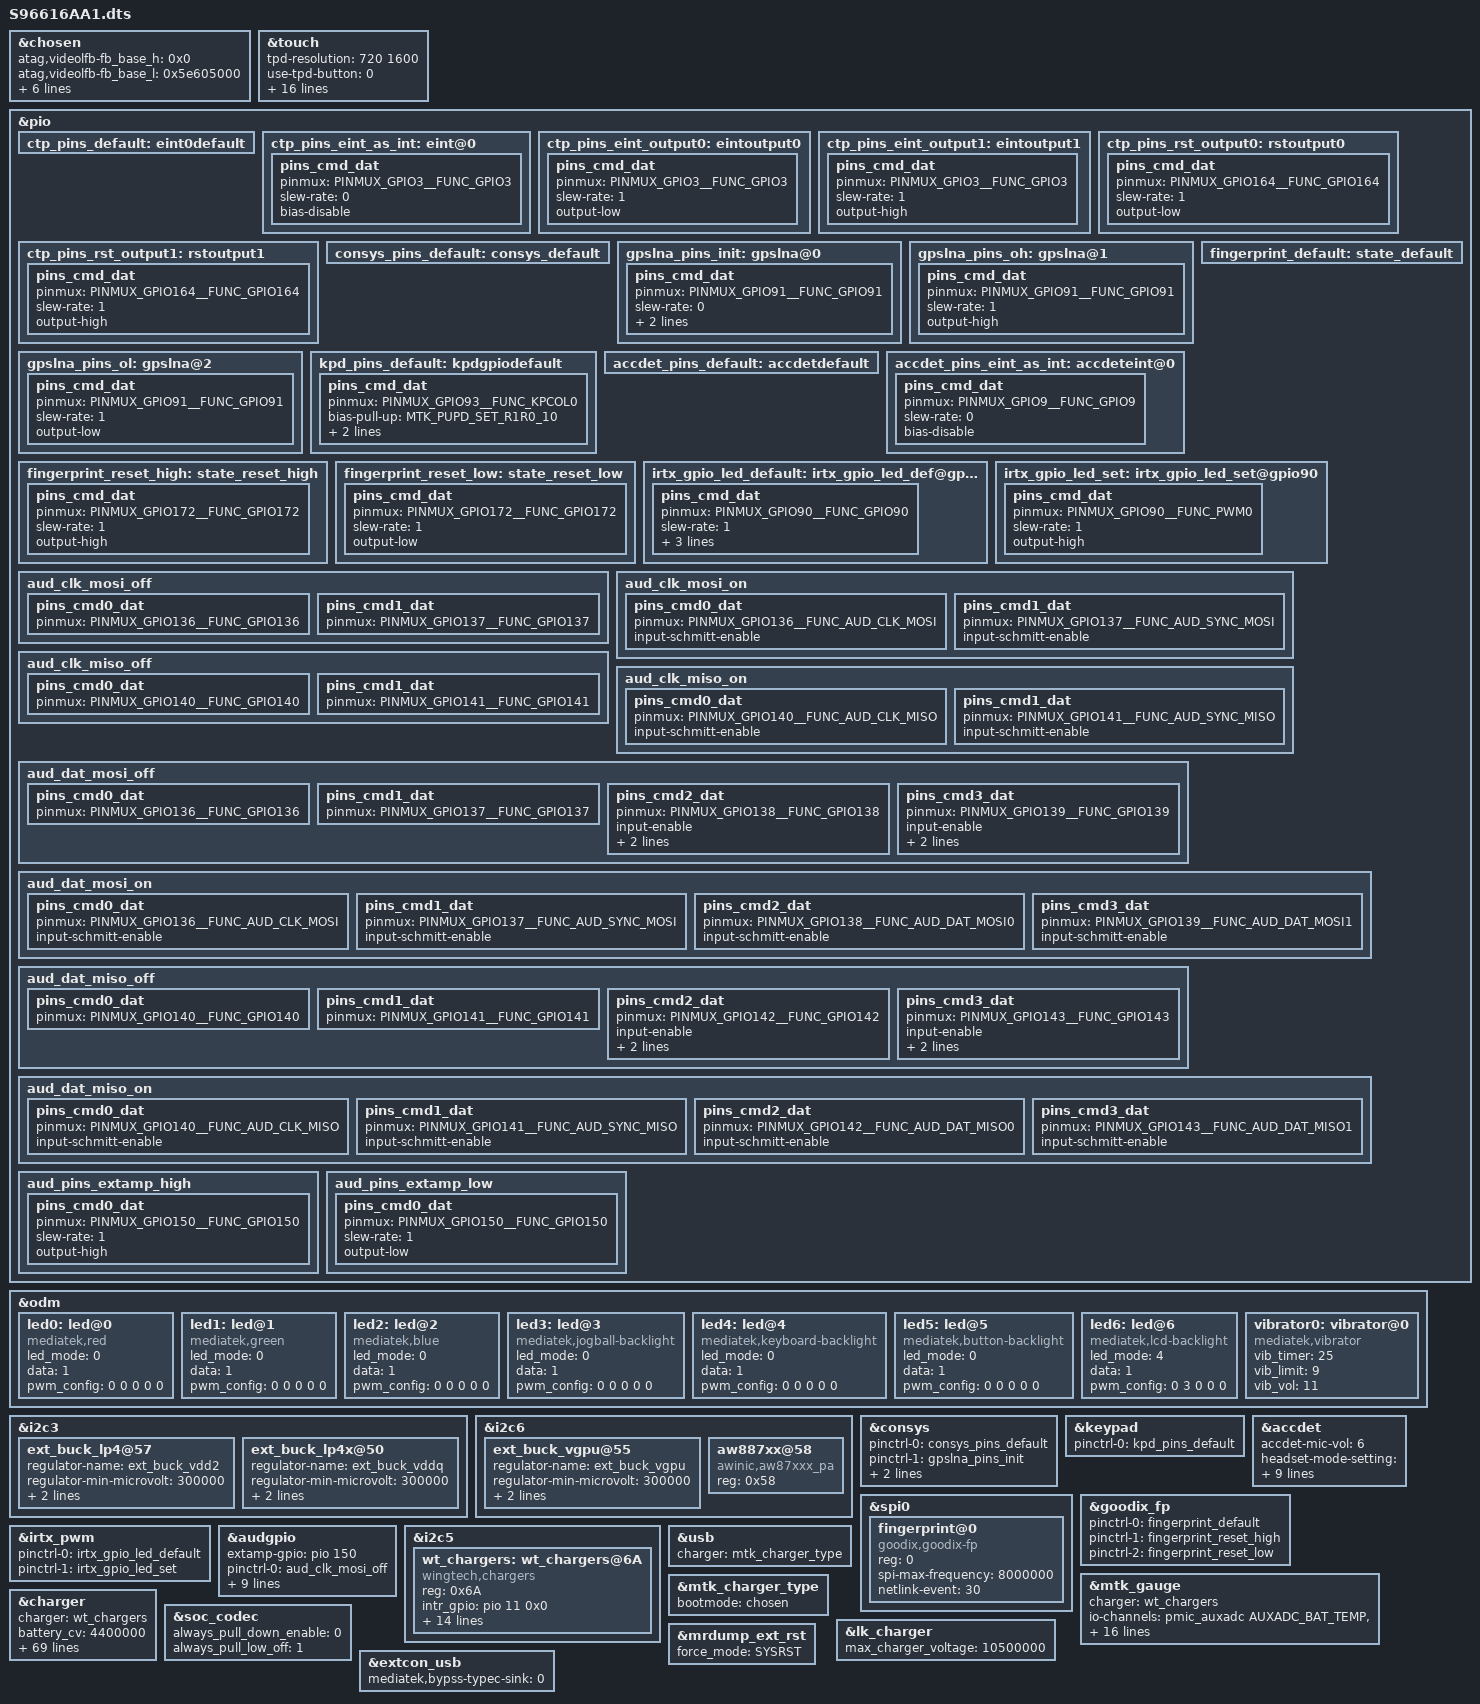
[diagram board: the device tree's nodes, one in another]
// SPDX-License-Identifier: GPL-2.0+
/*
 * Copyright (c) 2019 MediaTek Inc.
 *
 */

#include <dt-bindings/interrupt-controller/arm-gic.h>
#include <dt-bindings/interrupt-controller/irq.h>
#include <dt-bindings/pinctrl/mt6765-pinfunc.h>
#include <dt-bindings/clock/mt6765-clk.h>

/dts-v1/;
/plugin/;

/* chosen */
&chosen {

	/* fpga may has no lk, we need to specify display info here */
	/* fb buffer is reserved using this dts by memory node above */
	atag,videolfb-fb_base_h = <0x0>;
	atag,videolfb-fb_base_l = <0x5e605000>;
	atag,videolfb-islcmfound = <1>;
	/* because no lk, so lcm is not inited */
	atag,videolfb-islcm_inited = <0>;
	atag,videolfb-fps= <6000>;
	atag,videolfb-vramSize= <0x017bb000>;
	atag,videolfb-lcmname= "nt35695B_fhd_dsi_cmd_auo_rt5081_drv";
};

/* TOUCH start */
&touch {
	tpd-resolution = <720 1600>;
	use-tpd-button = <0>;
	tpd-key-num = <3>;
	tpd-key-local= <139 172 158 0>;
	tpd-key-dim-local = <200 2000 100 40 515 2000 100 40 800 2000 100 40 0 0 0 0>;
	tpd-max-touch-num = <10>;
	tpd-filter-enable = <0>;
	tpd-filter-pixel-density = <192>;
	tpd-filter-custom-prameters = <0 0 0 0 0 0 0 0 0 0 0 0>;
	tpd-filter-custom-speed = <0 0 0>;
	pinctrl-names = "default", "state_eint_as_int", "state_eint_output0",
		"state_eint_output1", "state_rst_output0", "state_rst_output1";
	pinctrl-0 = <&ctp_pins_default>;
	pinctrl-1 = <&ctp_pins_eint_as_int>;
	pinctrl-2 = <&ctp_pins_eint_output0>;
	pinctrl-3 = <&ctp_pins_eint_output1>;
	pinctrl-4 = <&ctp_pins_rst_output0>;
	pinctrl-5 = <&ctp_pins_rst_output1>;
	status = "okay";
};
&pio {
	ctp_pins_default: eint0default {
	};
	ctp_pins_eint_as_int: eint@0 {
		pins_cmd_dat {
			pinmux = <PINMUX_GPIO3__FUNC_GPIO3>;
			slew-rate = <0>;
			bias-disable;
		};
	};
	ctp_pins_eint_output0: eintoutput0 {
		pins_cmd_dat {
			pinmux = <PINMUX_GPIO3__FUNC_GPIO3>;
			slew-rate = <1>;
			output-low;
		};
	};
	ctp_pins_eint_output1: eintoutput1 {
		pins_cmd_dat {
			pinmux = <PINMUX_GPIO3__FUNC_GPIO3>;
			slew-rate = <1>;
			output-high;
		};
	};
	ctp_pins_rst_output0: rstoutput0 {
		pins_cmd_dat {
			pinmux = <PINMUX_GPIO164__FUNC_GPIO164>;
			slew-rate = <1>;
			output-low;
		};
	};
	ctp_pins_rst_output1: rstoutput1 {
		pins_cmd_dat {
			pinmux = <PINMUX_GPIO164__FUNC_GPIO164>;
			slew-rate = <1>;
			output-high;
		};
	};
};
/* TOUCH end */

&odm {
	led0:led@0 {
		compatible = "mediatek,red";
		led_mode = <0>;
		data = <1>;
		pwm_config = <0 0 0 0 0>;
	};
	led1:led@1 {
		compatible = "mediatek,green";
		led_mode = <0>;
		data = <1>;
		pwm_config = <0 0 0 0 0>;
	};
	led2:led@2 {
		compatible = "mediatek,blue";
		led_mode = <0>;
		data = <1>;
		pwm_config = <0 0 0 0 0>;
	};
	led3:led@3 {
		compatible = "mediatek,jogball-backlight";
		led_mode = <0>;
		data = <1>;
		pwm_config = <0 0 0 0 0>;
	};
	led4:led@4 {
		compatible = "mediatek,keyboard-backlight";
		led_mode = <0>;
		data = <1>;
		pwm_config = <0 0 0 0 0>;
	};
	led5:led@5 {
		compatible = "mediatek,button-backlight";
		led_mode = <0>;
		data = <1>;
		pwm_config = <0 0 0 0 0>;
	};
	led6:led@6 {
		compatible = "mediatek,lcd-backlight";
		led_mode = <4>;
		data = <1>;
		pwm_config = <0 3 0 0 0>;
	};
	vibrator0:vibrator@0 {
		compatible = "mediatek,vibrator";
		vib_timer = <25>;
		vib_limit = <9>;
		vib_vol= <11>;
	};
};

&i2c3 {
	ext_buck_lp4@57 {
		regulator-name ="ext_buck_vdd2";
		regulator-min-microvolt = <300000>;
		regulator-max-microvolt = <1300000>;
		vsel_pin = <0>;
	};

	ext_buck_lp4x@50 {
		regulator-name ="ext_buck_vddq";
		regulator-min-microvolt = <300000>;
		regulator-max-microvolt = <1300000>;
		vsel_pin = <1>;
	};
};

&i2c6 {
	ext_buck_vgpu@55 {
		regulator-name ="ext_buck_vgpu";
		regulator-min-microvolt = <300000>;
		regulator-max-microvolt = <1300000>;
		vsel_pin = <2>;
	};
};

&i2c6 {
    aw887xx@58 {
         compatible = "awinic,aw87xxx_pa";
         reg = <0x58>;
         status = "okay";
    };
};

/* CONSYS GPIO standardization */
&pio {
	consys_pins_default: consys_default {
	};
	gpslna_pins_init: gpslna@0 {
		pins_cmd_dat {
			pinmux = <PINMUX_GPIO91__FUNC_GPIO91>;
			slew-rate = <0>;
			bias-disable;
			output-low;
		};
	};
	gpslna_pins_oh: gpslna@1 {
		pins_cmd_dat {
			pinmux = <PINMUX_GPIO91__FUNC_GPIO91>;
			slew-rate = <1>;
			output-high;
		};
	};
	gpslna_pins_ol: gpslna@2 {
		pins_cmd_dat {
			pinmux = <PINMUX_GPIO91__FUNC_GPIO91>;
			slew-rate = <1>;
			output-low;
		};
	};
};
&consys {
	pinctrl-names = "default", "gps_lna_state_init",
		"gps_lna_state_oh", "gps_lna_state_ol";
	pinctrl-0 = <&consys_pins_default>;
	pinctrl-1 = <&gpslna_pins_init>;
	pinctrl-2 = <&gpslna_pins_oh>;
	pinctrl-3 = <&gpslna_pins_ol>;
	status = "okay";
};
/* CONSYS end */

&keypad {
	pinctrl-names = "default";
	pinctrl-0 = <&kpd_pins_default>;
};

&pio {
	kpd_pins_default: kpdgpiodefault {
		pins_cmd_dat {
			pinmux = <PINMUX_GPIO93__FUNC_KPCOL0>;
			bias-pull-up = <MTK_PUPD_SET_R1R0_10>;
			output-low;
			input-schmitt-enable;
		};
	};
};


/* accdet start */
&accdet {
	accdet-mic-vol = <6>;
	headset-mode-setting = <0x500 0x500 1 0x1f0 0x800 0x800 0x20 0x44>;
	accdet-plugout-debounce = <1>;
	accdet-mic-mode = <1>;
	headset-eint-level-pol = <8>;
	headset-three-key-threshold = <0 80 220 400>;
	headset-three-key-threshold-CDD = <0 121 192 600>;
	headset-four-key-threshold = <0 58 121 192 400>;
	pinctrl-names = "default", "state_eint_as_int";
	pinctrl-0 = <&accdet_pins_default>;
	pinctrl-1 = <&accdet_pins_eint_as_int>;
	status = "okay";
};
&pio {
	accdet_pins_default: accdetdefault {
	};
	accdet_pins_eint_as_int: accdeteint@0 {
		pins_cmd_dat {
			pinmux = <PINMUX_GPIO9__FUNC_GPIO9>;
			slew-rate = <0>;
			bias-disable;
		};
	};
};
/* accdet end */

/* FINGERPRINT start */
&spi0 {
	#address-cells = <1>;
	#size-cells = <0>;
	fingerprint@0 {
		compatible = "goodix,goodix-fp";
		reg = <0>;
		spi-max-frequency = <8000000>;
		netlink-event = <30>;
		status = "okay";
	};
};

&goodix_fp {
	pinctrl-names = "default", "reset_high", "reset_low";
	pinctrl-0 = <&fingerprint_default>;
	pinctrl-1 = <&fingerprint_reset_high>;
	pinctrl-2 = <&fingerprint_reset_low>;
	status = "okay";
};

&pio {
	fingerprint_default: state_default {
	};
	fingerprint_reset_high: state_reset_high {
		pins_cmd_dat {
			pinmux = <PINMUX_GPIO172__FUNC_GPIO172>;
			slew-rate = <1>;
			output-high;
		};
	};
	fingerprint_reset_low: state_reset_low {
		pins_cmd_dat {
			pinmux = <PINMUX_GPIO172__FUNC_GPIO172>;
			slew-rate = <1>;
			output-low;
		};
	};
};
/* FINGERPRINT end */

/* IRTX GPIO end */
&irtx_pwm {
	pinctrl-names = "irtx_gpio_led_default", "irtx_gpio_led_set";
	pinctrl-0 = <&irtx_gpio_led_default>;
	pinctrl-1 = <&irtx_gpio_led_set>;
	status = "okay";
};
&pio {
	irtx_gpio_led_default:irtx_gpio_led_def@gpio90 {
		pins_cmd_dat {
			pinmux = <PINMUX_GPIO90__FUNC_GPIO90>;
			slew-rate = <1>;
			bias-disable;
			output-low;
			input-schmitt-enable = <0>;
		};
	};

	irtx_gpio_led_set:irtx_gpio_led_set@gpio90 {
		pins_cmd_dat {
			pinmux = <PINMUX_GPIO90__FUNC_PWM0>;
			slew-rate = <1>;
			output-high;
		};
	};
};
/* IRTX GPIO Settings -End */

/* AUDIO GPIO standardization */
&audgpio {
	extamp-gpio = <&pio 150 0>;
	pinctrl-names = "aud_clk_mosi_off",
			"aud_clk_mosi_on",
			"aud_clk_miso_off",
			"aud_clk_miso_on",
			"aud_dat_mosi_off",
			"aud_dat_mosi_on",
			"aud_dat_miso_off",
			"aud_dat_miso_on",
			"extamp_pullhigh",
			"extamp_pulllow";
	pinctrl-0 = <&aud_clk_mosi_off>;
	pinctrl-1 = <&aud_clk_mosi_on>;
	pinctrl-2 = <&aud_clk_miso_off>;
	pinctrl-3 = <&aud_clk_miso_on>;
	pinctrl-4 = <&aud_dat_mosi_off>;
	pinctrl-5 = <&aud_dat_mosi_on>;
	pinctrl-6 = <&aud_dat_miso_off>;
	pinctrl-7 = <&aud_dat_miso_on>;
	pinctrl-8 = <&aud_pins_extamp_high>;
	pinctrl-9 = <&aud_pins_extamp_low>;
	status = "okay";
};

&pio {
	aud_clk_mosi_off: aud_clk_mosi_off {
		pins_cmd0_dat {
			pinmux = <PINMUX_GPIO136__FUNC_GPIO136>;
		};
		pins_cmd1_dat {
			pinmux = <PINMUX_GPIO137__FUNC_GPIO137>;
		};

	};

	aud_clk_mosi_on: aud_clk_mosi_on {
		pins_cmd0_dat {
			pinmux = <PINMUX_GPIO136__FUNC_AUD_CLK_MOSI>;
			input-schmitt-enable;
		};
		pins_cmd1_dat {
			pinmux = <PINMUX_GPIO137__FUNC_AUD_SYNC_MOSI>;
			input-schmitt-enable;
		};
	};

	aud_clk_miso_off: aud_clk_miso_off {
		pins_cmd0_dat {
			pinmux = <PINMUX_GPIO140__FUNC_GPIO140>;
		};
		pins_cmd1_dat {
			pinmux = <PINMUX_GPIO141__FUNC_GPIO141>;
		};
	};

	aud_clk_miso_on: aud_clk_miso_on {
		pins_cmd0_dat {
			pinmux = <PINMUX_GPIO140__FUNC_AUD_CLK_MISO>;
			input-schmitt-enable;
		};
		pins_cmd1_dat {
			pinmux = <PINMUX_GPIO141__FUNC_AUD_SYNC_MISO>;
			input-schmitt-enable;
		};
	};

	aud_dat_mosi_off: aud_dat_mosi_off {
		pins_cmd0_dat {
			pinmux = <PINMUX_GPIO136__FUNC_GPIO136>;
		};
		pins_cmd1_dat {
			pinmux = <PINMUX_GPIO137__FUNC_GPIO137>;
		};
		pins_cmd2_dat {
			pinmux = <PINMUX_GPIO138__FUNC_GPIO138>;
			input-enable;
			slew-rate = <0>;
			bias-disable;
		};
		pins_cmd3_dat {
			pinmux = <PINMUX_GPIO139__FUNC_GPIO139>;
			input-enable;
			slew-rate = <0>;
			bias-disable;
		};
	};

	aud_dat_mosi_on: aud_dat_mosi_on {
		pins_cmd0_dat {
			pinmux = <PINMUX_GPIO136__FUNC_AUD_CLK_MOSI>;
			input-schmitt-enable;
		};
		pins_cmd1_dat {
			pinmux = <PINMUX_GPIO137__FUNC_AUD_SYNC_MOSI>;
			input-schmitt-enable;
		};
		pins_cmd2_dat {
			pinmux = <PINMUX_GPIO138__FUNC_AUD_DAT_MOSI0>;
			input-schmitt-enable;
		};
		pins_cmd3_dat {
			pinmux = <PINMUX_GPIO139__FUNC_AUD_DAT_MOSI1>;
			input-schmitt-enable;
		};
	};

	aud_dat_miso_off: aud_dat_miso_off {
		pins_cmd0_dat {
			pinmux = <PINMUX_GPIO140__FUNC_GPIO140>;
		};
		pins_cmd1_dat {
			pinmux = <PINMUX_GPIO141__FUNC_GPIO141>;
		};
		pins_cmd2_dat {
			pinmux = <PINMUX_GPIO142__FUNC_GPIO142>;
			input-enable;
			slew-rate = <0>;
			bias-disable;
		};
		pins_cmd3_dat {
			pinmux = <PINMUX_GPIO143__FUNC_GPIO143>;
			input-enable;
			slew-rate = <0>;
			bias-disable;
		};
	};
	aud_dat_miso_on: aud_dat_miso_on {
		pins_cmd0_dat {
			pinmux = <PINMUX_GPIO140__FUNC_AUD_CLK_MISO>;
			input-schmitt-enable;
		};
		pins_cmd1_dat {
			pinmux = <PINMUX_GPIO141__FUNC_AUD_SYNC_MISO>;
			input-schmitt-enable;
		};
		pins_cmd2_dat {
			pinmux = <PINMUX_GPIO142__FUNC_AUD_DAT_MISO0>;
			input-schmitt-enable;
		};
		pins_cmd3_dat {
			pinmux = <PINMUX_GPIO143__FUNC_AUD_DAT_MISO1>;
			input-schmitt-enable;
		};
	};

	aud_pins_extamp_high: aud_pins_extamp_high {
		pins_cmd0_dat {
			pinmux = <PINMUX_GPIO150__FUNC_GPIO150>;
			slew-rate = <1>;
			output-high;
		};
	};
	aud_pins_extamp_low: aud_pins_extamp_low {
		pins_cmd0_dat {
			pinmux = <PINMUX_GPIO150__FUNC_GPIO150>;
			slew-rate = <1>;
			output-low;
		};
	};
};

&i2c5 {
    wt_chargers:wt_chargers@6A {
		compatible = "wingtech,chargers";
		reg = <0x6A>;
		intr_gpio = <&pio 11 0x0>;
		intr_gpio_num = <11>;
		charger_name = "primary_chg";
		termination-current = <260000>;
		boost-voltage = <5000000>;
		boost-current = <1200000>;
		charger = <&mtk_charger_type>;
		afc_switch_gpio_num = <178>;
		afc_switch_gpio = <&pio 178 0x0>;
		afc_data_gpio_num = <41>;
		afc_data_gpio = <&pio 41 0x0>;
		afc_start_battery_soc = <0>;
		afc_stop_battery_soc = <90>;
		afc_charger_input_current = <1670000>;
		afc_charger_current = <3000000>;
		status = "okay";
    };
};
#include <dt-bindings/iio/mt635x-auxadc.h>
&mtk_gauge {
	charger = <&wt_chargers>;
	io-channels = <&pmic_auxadc AUXADC_BAT_TEMP>,
			<&pmic_auxadc AUXADC_ISENSE>,
			<&pmic_auxadc AUXADC_VBIF>,
			<&pmic_auxadc AUXADC_IMP>,
			<&pmic_auxadc AUXADC_IMIX_R>,
			<&auxadc 4>;
	io-channel-names = "pmic_battery_temp",
			"pmic_battery_voltage",
			"pmic_bif_voltage",
			"pmic_ptim_voltage",
			"pmic_ptim_r",
			"battery_id";
/*+S96616AA3-534 lijiawei,wt.battery cycle function and otg control function*/
wt,batt-cycle-ranges = <
		0   299  4400000
		300 399  4380000
		400 699  4360000
		700 999  4340000
		1000 999999 4290000>;
	g_FG_PSEUDO100_cv4400 = <
		100 100 100 100
		100 100 100 100
		100 100 100 100
		90 90 90 100
		90 90 90 100
		100 100 100 100
		100 100 100 100
		100 100 100 100
		100 100 100 100
		100 100 100 100>;
	g_FG_PSEUDO100_cv4380 = <
		98 98 98 100
		99 98 98 100
		99 98 98 100
		99 98 98 100
		99 99 99 100
		100 100 100 100
		100 100 100 100
		100 100 100 100
		100 100 100 100
		100 100 100 100>;
	g_FG_PSEUDO100_cv4360 = <
		97 96 96 100
		97 96 96 100
		97 96 96 100
		98 96 96 100
		98 97 97 100
		100 100 100 100
		100 100 100 100
		100 100 100 100
		100 100 100 100
		100 100 100 100>;
	g_FG_PSEUDO100_cv4340 = <
		96 95 95 100
		96 95 95 100
		96 94 94 100
		97 95 95 100
		97 96 96 100
		100 100 100 100
		100 100 100 100
		100 100 100 100
		100 100 100 100
		100 100 100 100>;
	g_FG_PSEUDO100_cv4290 = <
		92 90 90 100
		92 90 90 100
		92 90 90 100
		93 91 91 100
		94 92 92 100
		100 100 100 100
		100 100 100 100
		100 100 100 100
		100 100 100 100
		100 100 100 100>;
/*-S96616AA3-534 lijiawei,wt.battery cycle function and otg control function*/
};

&usb {
	charger = <&mtk_charger_type>;
};
&mtk_charger_type {
	bootmode = <&chosen>;
};
&charger {
	charger = <&wt_chargers>;
	battery_cv = <4400000>;
	enable_sw_jeita;
	jeita_temp_above_t4_cv = <4100000>;
	jeita_temp_t3_to_t4_cv = <4100000>;
	jeita_temp_t2_to_t3_cv = <4400000>;
	jeita_temp_t1_to_t2_cv = <4400000>;
	jeita_temp_t0_to_t1_cv = <4400000>;
	jeita_temp_below_t0_cv = <4400000>;
	jeita_temp_above_t4_cc = <0>;
	jeita_temp_t3_to_t4_cc = <1400000>;
	jeita_temp_t2_to_t3_cc = <2000000>;
	jeita_temp_t1_to_t2_cc = <1200000>;
	jeita_temp_t0_to_t1_cc = <400000>;
	jeita_temp_below_t0_cc = <0>;
	jeita_temp_above_t4_fast_cc = <0>;
	jeita_temp_t3_to_t4_fast_cc = <1400000>;
	jeita_temp_t2_to_t3_fast_cc = <3000000>;
	jeita_temp_t1_to_t2_fast_cc = <1200000>;
	jeita_temp_t0_to_t1_fast_cc = <400000>;
	jeita_temp_below_t0_fast_cc = <0>;

	temp_t4_thres = <55>;
	temp_t4_thres_minus_x_degree = <54>;
	temp_t3_thres = <45>;
	temp_t3_thres_minus_x_degree = <44>;
	temp_t2_thres = <10>;
	temp_t2_thres_plus_x_degree = <11>;
	temp_t1_thres = <5>;
	temp_t1_thres_plus_x_degree = <6>;
	temp_t0_thres = <0>;
	temp_t0_thres_plus_x_degree = <1>;

	ap_temp_lcmoff_above_t2_cc = <500000>;
	ap_temp_lcmoff_t1_to_t2_cc = <1400000>;
	ap_temp_lcmoff_t0_to_t1_cc = <2000000>;
	ap_temp_lcmoff_below_t0_cc = <2800000>;
//+P240111-05098   guhan01.wt 2024031820,Modify the maximum current limit for bright screen charging
//	ap_temp_lcmon_above_t0_cc = <500000>;
//	ap_temp_lcmon_below_t0_cc = <800000>;

	ap_temp_lcmon_above_t4 = <300000>;
	ap_temp_lcmon_t3_to_t4 = <600000>;
	ap_temp_lcmon_t2_to_t3 = <1000000>;
	ap_temp_lcmon_t1_to_t2 = <2000000>;
	ap_temp_lcmon_t0_to_t1 = <2500000>;
	ap_temp_lcmon_below_t0 = <3000000>;
//-P240111-05098   guhan01.wt 2024031820,Modify the maximum current limit for bright screen charging
	ap_lcmoff_t2_thres = <48>;
	ap_lcmoff_t2_thres_plus_x_degree = <48>;
	ap_lcmoff_t1_thres = <45>;
	ap_lcmoff_t1_thres_plus_x_degree = <45>;
	ap_lcmoff_t0_thres = <40>;
	ap_lcmoff_t0_thres_plus_x_degree = <39>;
//+P240111-05098   guhan01.wt 2024031820,Modify the maximum current limit for bright screen charging
//	ap_lcmon_t0_thres = <44>;
//	ap_lcmon_t0_thres_plus_x_degree = <42>;

	ap_temp_lcmon_t4 = <45>;
	ap_temp_lcmon_t3 = <43>;
	ap_temp_lcmon_t2 = <42>;
	ap_temp_lcmon_t1 = <41>;
	ap_temp_lcmon_t0 = <39>;

	ap_temp_lcmon_t4_anti_shake = <43>;
	ap_temp_lcmon_t3_anti_shake = <41>;
	ap_temp_lcmon_t2_anti_shake = <40>;
	ap_temp_lcmon_t1_anti_shake = <39>;
	ap_temp_lcmon_t0_anti_shake = <37>;
//-P240111-05098   guhan01.wt 2024031820,Modify the maximum current limit for bright screen charging
	min_charge_temp = <0>;
	min_charge_temp_plus_x_degree = <6>;
	max_charge_temp = <55>;
	max_charge_temp_minus_x_degree = <47>;

	/* charging current */
	usb_charger_current = <500000>;
	ac_charger_current = <2000000>;
	ac_charger_input_current = <1550000>;
	charging_host_charger_current = <1000000>;
	fast_charger_current = <3000000>;
	fast_charger_input_current = <1670000>;
	/* dynamic mivr */
	enable_dynamic_mivr;
	min_charger_voltage_1 = <4400000>;
	min_charger_voltage_2 = <4200000>;
	max_dmivr_charger_current = <1800000>;
};

&soc_codec {
	always_pull_down_enable = <0>; /* select 1: enable, 0: disable */
	always_pull_low_off = <1>; /* select 1: enable, 0: disable */
};
/* AUDIO end */



&lk_charger {
	max_charger_voltage = <10500000>;
};

&extcon_usb {
	mediatek,bypss-typec-sink = <0>;
};

/*+bug 798884, douyingnan.wt, add, 20220901, powerkey + volume down enter dump*/
&mrdump_ext_rst {
        force_mode = "SYSRST";
};
/*+bug 798884, douyingnan.wt, add, 20220901, powerkey + volume down enter dump*/
#include "mediatek/S96616AA1/cust.dtsi"
#include "mediatek/cust_mt6765_camera.dtsi"
#include "mediatek/cust_mt6765_lcm_module.dtsi"
#include "mediatek/cust_mt6765_touch_720x1600.dtsi"
/*End of this file, DO NOT ADD ANYTHING HERE*/
